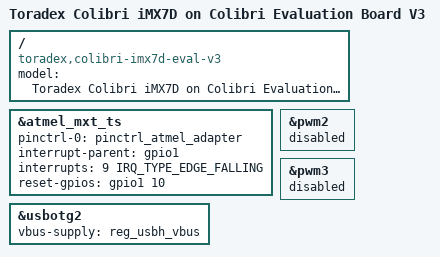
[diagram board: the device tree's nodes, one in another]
// SPDX-License-Identifier: GPL-2.0+ OR MIT
/*
 * Copyright 2016-2020 Toradex
 */

/dts-v1/;
#include "imx7d-colibri.dtsi"
#include "imx7-colibri-eval-v3.dtsi"

/ {
	model = "Toradex Colibri iMX7D on Colibri Evaluation Board V3";
	compatible = "toradex,colibri-imx7d-eval-v3",
		     "toradex,colibri-imx7d",
		     "fsl,imx7d";
};

&atmel_mxt_ts {
	pinctrl-0 = <&pinctrl_atmel_adapter>;
	interrupt-parent = <&gpio1>;
	interrupts = <9 IRQ_TYPE_EDGE_FALLING>;		/* SODIMM_28, INT */
	reset-gpios = <&gpio1 10 GPIO_ACTIVE_HIGH>;	/* SODIMM_30, RST */
	status = "okay";
};

&pwm2 {
	status = "disabled";
};

&pwm3 {
	status = "disabled";
};

&usbotg2 {
	vbus-supply = <&reg_usbh_vbus>;
	status = "okay";
};
